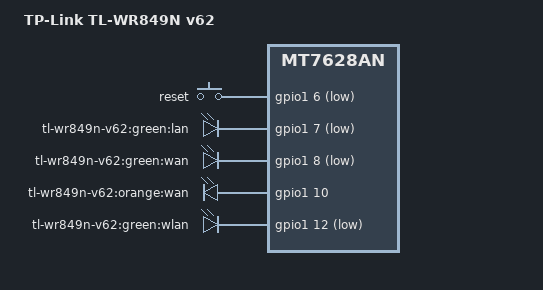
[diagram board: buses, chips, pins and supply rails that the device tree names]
/dts-v1/;

#include "TPLINK-4M-LF.dtsi"

#include <dt-bindings/gpio/gpio.h>
#include <dt-bindings/input/input.h>

/ {
	compatible = "tplink,tl-wr849n-v62", "mediatek,mt7628an-soc";
	model = "TP-Link TL-WR849N v62";

	aliases {
		led-boot = &led_power;
		led-failsafe = &led_power;
		led-running = &led_power;
		led-upgrade = &led_power;
	};

	keys {
		compatible = "gpio-keys-polled";
		poll-interval = <20>;

		reset {
			label = "reset";
			gpios = <&gpio1 6 GPIO_ACTIVE_LOW>;
			linux,code = <KEY_RESTART>;
		};
	};
	gpio-leds {
		compatible = "gpio-leds";

		lan {
			label = "tl-wr849n-v62:green:lan";
			gpios = <&gpio1 7 GPIO_ACTIVE_LOW>;
		};

		led_power: wan {
			label = "tl-wr849n-v62:green:wan";
			gpios = <&gpio1 8 GPIO_ACTIVE_LOW>;
		};

		wan_orange {
			label = "tl-wr849n-v62:orange:wan";
			gpios = <&gpio1 10 GPIO_ACTIVE_HIGH>;
		};

		wlan {
			label = "tl-wr849n-v62:green:wlan";
			gpios = <&gpio1 12 GPIO_ACTIVE_LOW>;
		};
	};
};

&pinctrl {
	state_default: pinctrl0 {
		gpio {
			ralink,group = "p0led_an", "p2led_an", "p3led_an", "p4led_an", "perst";
			ralink,function = "gpio";
		};
	};
};
